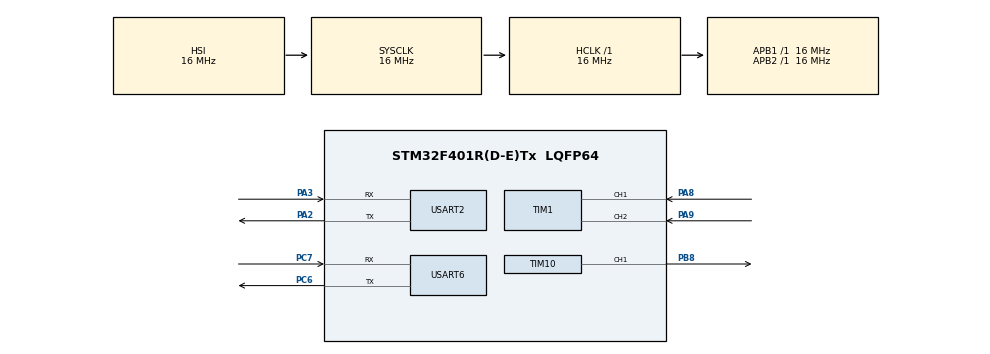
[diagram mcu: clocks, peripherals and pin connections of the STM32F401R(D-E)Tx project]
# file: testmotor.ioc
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Mcu.Family=STM32F4
Mcu.Name=STM32F401R(D-E)Tx
Mcu.Package=LQFP64
NVIC.PriorityGroup=NVIC_PRIORITYGROUP_4
PA2.Mode=Asynchronous
PA2.Signal=USART2_TX
PA3.Mode=Asynchronous
PA3.Signal=USART2_RX
PA8.Signal=S_TIM1_CH1
PA9.Signal=S_TIM1_CH2
PB8.Signal=S_TIM10_CH1
PC6.Mode=Asynchronous
PC6.Signal=USART6_TX
PC7.Mode=Asynchronous
PC7.Signal=USART6_RX
ProjectManager.HeapSize=0x200
ProjectManager.StackSize=0x400
ProjectManager.TargetToolchain=SW4STM32
RCC.AHBFreq_Value=16000000
RCC.APB1Freq_Value=16000000
RCC.APB2Freq_Value=16000000
RCC.CortexFreq_Value=16000000
RCC.HSE_VALUE=25000000
RCC.HSI_VALUE=16000000
RCC.LSE_VALUE=32768
RCC.SYSCLKFreq_VALUE=16000000
RCC.VCOOutputFreq_Value=192000000
SH.S_TIM10_CH1.0=TIM10_CH1,PWM Generation1 CH1
SH.S_TIM1_CH1.0=TIM1_CH1,Encoder_Interface
SH.S_TIM1_CH2.0=TIM1_CH2,Encoder_Interface
TIM10.Channel=TIM_CHANNEL_1
USART2.VirtualMode=VM_ASYNC
USART6.VirtualMode=VM_ASYNC
VP_TIM10_VS_ClockSourceINT.Mode=Enable_Timer
board=testmotor

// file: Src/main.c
/**
  ******************************************************************************
  * @file           : main.c
  * @brief          : Main program body
  ******************************************************************************
  ** This notice applies to any and all portions of this file
  * that are not between comment pairs USER CODE BEGIN and
  * USER CODE END. Other portions of this file, whether
  * inserted by the user or by software development tools
  * are owned by their respective copyright owners.
  *
  * COPYRIGHT(c) 2018 STMicroelectronics
  *
  * Redistribution and use in source and binary forms, with or without modification,
  * are permitted provided that the following conditions are met:
  *   1. Redistributions of source code must retain the above copyright notice,
  *      this list of conditions and the following disclaimer.
  *   2. Redistributions in binary form must reproduce the above copyright notice,
  *      this list of conditions and the following disclaimer in the documentation
  *      and/or other materials provided with the distribution.
  *   3. Neither the name of STMicroelectronics nor the names of its contributors
  *      may be used to endorse or promote products derived from this software
  *      without specific prior written permission.
  *
  * THIS SOFTWARE IS PROVIDED BY THE COPYRIGHT HOLDERS AND CONTRIBUTORS "AS IS"
  * AND ANY EXPRESS OR IMPLIED WARRANTIES, INCLUDING, BUT NOT LIMITED TO, THE
  * IMPLIED WARRANTIES OF MERCHANTABILITY AND FITNESS FOR A PARTICULAR PURPOSE ARE
  * DISCLAIMED. IN NO EVENT SHALL THE COPYRIGHT HOLDER OR CONTRIBUTORS BE LIABLE
  * FOR ANY DIRECT, INDIRECT, INCIDENTAL, SPECIAL, EXEMPLARY, OR CONSEQUENTIAL
  * DAMAGES (INCLUDING, BUT NOT LIMITED TO, PROCUREMENT OF SUBSTITUTE GOODS OR
  * SERVICES; LOSS OF USE, DATA, OR PROFITS; OR BUSINESS INTERRUPTION) HOWEVER
  * CAUSED AND ON ANY THEORY OF LIABILITY, WHETHER IN CONTRACT, STRICT LIABILITY,
  * OR TORT (INCLUDING NEGLIGENCE OR OTHERWISE) ARISING IN ANY WAY OUT OF THE USE
  * OF THIS SOFTWARE, EVEN IF ADVISED OF THE POSSIBILITY OF SUCH DAMAGE.
  *
  ******************************************************************************
  */
#include "main.h"
#include "stm32f4xx_hal.h"

TIM_HandleTypeDef htim1;
TIM_HandleTypeDef htim10;

UART_HandleTypeDef huart2;
UART_HandleTypeDef huart6;

/* USER CODE BEGIN PV */
/* Private variables ---------------------------------------------------------*/

/* USER CODE END PV */

void SystemClock_Config(void);
static void MX_GPIO_Init(void);
static void MX_TIM1_Init(void);
static void MX_USART2_UART_Init(void);
static void MX_TIM10_Init(void);
static void MX_USART6_UART_Init(void);

void HAL_TIM_MspPostInit(TIM_HandleTypeDef *htim);

/* USER CODE BEGIN PFP */
/* Private function prototypes -----------------------------------------------*/

/* USER CODE END PFP */

int main(void)
{

  /* MCU Configuration----------------------------------------------------------*/

  /* Reset of all peripherals, Initializes the Flash interface and the Systick. */
  HAL_Init();

  /* Configure the system clock */
  SystemClock_Config();

  /* Initialize all configured peripherals */
  MX_GPIO_Init();
  MX_TIM1_Init();
  MX_USART2_UART_Init();
  MX_TIM10_Init();
  MX_USART6_UART_Init();
  HAL_TIM_Encoder_Start(&htim1, TIM_CHANNEL_ALL);

  /* USER CODE BEGIN 2 */
	uint16_t cnt1 = 0, cnt2 = 0;
	uint32_t tick = 0;
	uint16_t diff = 0;
  /* USER CODE END 2 */
	uint8_t i;

	char address = 128;
	char command = 11;
	char speed = 0;
	char checksum = (address + command + speed) & 0b01111111;

	HAL_Delay(2000);
	/* HAL_UART_Transmit(&huart2, (uint8_t*)&address, sizeof(address), 0xFFFFFF);
	HAL_UART_Transmit(&huart2, (uint8_t*)&command, sizeof(command), 0xFFFFFF);

	HAL_UART_Transmit(&huart2, (uint8_t*) &speed, sizeof(speed), 0xFFFFFF);
	HAL_UART_Transmit(&huart2, (uint8_t*) &checksum, sizeof(checksum),0xFFFFFF);
	HAL_Delay(2); */

    HAL_UART_Transmit(&huart6, (uint8_t*)&address, sizeof(address), 0xFFFFFF);
    HAL_UART_Transmit(&huart6, (uint8_t*)&command, sizeof(command), 0xFFFFFF);
    HAL_UART_Transmit(&huart6, (uint8_t*)&speed, sizeof(speed), 0xFFFFFF);
    HAL_UART_Transmit(&huart6, (uint8_t*)&checksum, sizeof(checksum), 0xFFFFFF);

	HAL_Delay(2000);

	char command2 = 8;
	char speed2 = 20;

	char checksum2 = (address + command2 + speed2) & 0b01111111;
	HAL_UART_Transmit(&huart6, (uint8_t*)&address, sizeof(address), 0xFFFFFF);
	HAL_UART_Transmit(&huart6, (uint8_t*)&command2, sizeof(command2), 0xFFFFFF);
	HAL_UART_Transmit(&huart6, (uint8_t*)&speed2, sizeof(speed2), 0xFFFFFF);
	HAL_UART_Transmit(&huart6, (uint8_t*)&checksum2, sizeof(checksum2), 0xFFFFFF);

	HAL_Delay(2000);

  /* Infinite loop */
  /* USER CODE BEGIN WHILE */
    char msg[80];

	while (1) {

		if (HAL_GetTick() - tick > 1000L) {
					cnt2 = __HAL_TIM_GET_COUNTER(&htim1);
					if (__HAL_TIM_IS_TIM_COUNTING_DOWN(&htim1)) {
						if (cnt2 < cnt1)
							diff = cnt1 - cnt2;
						else
							diff = (65535 - cnt2) + cnt1;
					} else {
						if (cnt2 > cnt1)
							diff = cnt2 - cnt1;
						else
							diff = (65535 - cnt1) + cnt2;
					}

					sprintf(msg, "Difference: %d\r\n", diff);
					HAL_UART_Transmit(&huart2, (uint8_t*)msg, strlen(msg),0xFFFF);

					sprintf(msg, "CNT1: %d\r\n", cnt1);
					HAL_UART_Transmit(&huart2, (uint8_t*) msg, strlen(msg), 0xFFFF);
					sprintf(msg, "CNT2: %d\r\n", cnt2);
					HAL_UART_Transmit(&huart2, (uint8_t*) msg, strlen(msg), 0xFFFF);

					speed = ((diff / 4) / 60);

					if ((TIM1->SMCR & 0x3) == 0x3) {
						speed /= 2;
					}

					sprintf(msg, "Speed: %d\r\n", speed);
					HAL_UART_Transmit(&huart2, (uint8_t*)msg, strlen(msg),0xFFFF);

					tick = HAL_GetTick();
				    cnt1 = __HAL_TIM_GET_COUNTER(&htim1);

				}

	}
  /* USER CODE END 3 */

}

void SystemClock_Config(void)
{

  RCC_OscInitTypeDef RCC_OscInitStruct;
  RCC_ClkInitTypeDef RCC_ClkInitStruct;

    /**Configure the main internal regulator output voltage
    */
  __HAL_RCC_PWR_CLK_ENABLE();

  __HAL_PWR_VOLTAGESCALING_CONFIG(PWR_REGULATOR_VOLTAGE_SCALE2);

    /**Initializes the CPU, AHB and APB busses clocks
    */
  RCC_OscInitStruct.OscillatorType = RCC_OSCILLATORTYPE_HSI;
  RCC_OscInitStruct.HSIState = RCC_HSI_ON;
  RCC_OscInitStruct.HSICalibrationValue = 16;
  RCC_OscInitStruct.PLL.PLLState = RCC_PLL_NONE;
  if (HAL_RCC_OscConfig(&RCC_OscInitStruct) != HAL_OK)
  {
    _Error_Handler(__FILE__, __LINE__);
  }

    /**Initializes the CPU, AHB and APB busses clocks
    */
  RCC_ClkInitStruct.ClockType = RCC_CLOCKTYPE_HCLK|RCC_CLOCKTYPE_SYSCLK
                              |RCC_CLOCKTYPE_PCLK1|RCC_CLOCKTYPE_PCLK2;
  RCC_ClkInitStruct.SYSCLKSource = RCC_SYSCLKSOURCE_HSI;
  RCC_ClkInitStruct.AHBCLKDivider = RCC_SYSCLK_DIV1;
  RCC_ClkInitStruct.APB1CLKDivider = RCC_HCLK_DIV1;
  RCC_ClkInitStruct.APB2CLKDivider = RCC_HCLK_DIV1;

  if (HAL_RCC_ClockConfig(&RCC_ClkInitStruct, FLASH_LATENCY_0) != HAL_OK)
  {
    _Error_Handler(__FILE__, __LINE__);
  }

    /**Configure the Systick interrupt time
    */
  HAL_SYSTICK_Config(HAL_RCC_GetHCLKFreq()/1000);

    /**Configure the Systick
    */
  HAL_SYSTICK_CLKSourceConfig(SYSTICK_CLKSOURCE_HCLK);

  /* SysTick_IRQn interrupt configuration */
  HAL_NVIC_SetPriority(SysTick_IRQn, 0, 0);
}

/* TIM1 init function */
static void MX_TIM1_Init(void)
{

  TIM_Encoder_InitTypeDef sConfig;
  TIM_MasterConfigTypeDef sMasterConfig;

  htim1.Instance = TIM1;
  htim1.Init.Prescaler = 0;
  htim1.Init.CounterMode = TIM_COUNTERMODE_UP;
  htim1.Init.Period = 65535;
  htim1.Init.ClockDivision = TIM_CLOCKDIVISION_DIV1;
  htim1.Init.RepetitionCounter = 0;
  sConfig.EncoderMode = TIM_ENCODERMODE_TI12;
  sConfig.IC1Polarity = TIM_ICPOLARITY_RISING;
  sConfig.IC1Selection = TIM_ICSELECTION_DIRECTTI;
  sConfig.IC1Prescaler = TIM_ICPSC_DIV1;
  sConfig.IC1Filter = 0;
  sConfig.IC2Polarity = TIM_ICPOLARITY_RISING;
  sConfig.IC2Selection = TIM_ICSELECTION_DIRECTTI;
  sConfig.IC2Prescaler = TIM_ICPSC_DIV1;
  sConfig.IC2Filter = 0;
  if (HAL_TIM_Encoder_Init(&htim1, &sConfig) != HAL_OK)
  {
    _Error_Handler(__FILE__, __LINE__);
  }

  sMasterConfig.MasterOutputTrigger = TIM_TRGO_RESET;
  sMasterConfig.MasterSlaveMode = TIM_MASTERSLAVEMODE_DISABLE;
  if (HAL_TIMEx_MasterConfigSynchronization(&htim1, &sMasterConfig) != HAL_OK)
  {
    _Error_Handler(__FILE__, __LINE__);
  }

}

/* TIM10 init function */
static void MX_TIM10_Init(void)
{

  TIM_OC_InitTypeDef sConfigOC;

  htim10.Instance = TIM10;
  htim10.Init.Prescaler = 0;
  htim10.Init.CounterMode = TIM_COUNTERMODE_UP;
  htim10.Init.Period = 0;
  htim10.Init.ClockDivision = TIM_CLOCKDIVISION_DIV1;
  if (HAL_TIM_Base_Init(&htim10) != HAL_OK)
  {
    _Error_Handler(__FILE__, __LINE__);
  }

  if (HAL_TIM_PWM_Init(&htim10) != HAL_OK)
  {
    _Error_Handler(__FILE__, __LINE__);
  }

  sConfigOC.OCMode = TIM_OCMODE_PWM1;
  sConfigOC.Pulse = 0;
  sConfigOC.OCPolarity = TIM_OCPOLARITY_HIGH;
  sConfigOC.OCFastMode = TIM_OCFAST_DISABLE;
  if (HAL_TIM_PWM_ConfigChannel(&htim10, &sConfigOC, TIM_CHANNEL_1) != HAL_OK)
  {
    _Error_Handler(__FILE__, __LINE__);
  }

  HAL_TIM_MspPostInit(&htim10);

}

/* USART2 init function */
static void MX_USART2_UART_Init(void)
{

  huart2.Instance = USART2;
  huart2.Init.BaudRate = 115200;
  huart2.Init.WordLength = UART_WORDLENGTH_8B;
  huart2.Init.StopBits = UART_STOPBITS_1;
  huart2.Init.Parity = UART_PARITY_NONE;
  huart2.Init.Mode = UART_MODE_TX_RX;
  huart2.Init.HwFlowCtl = UART_HWCONTROL_NONE;
  huart2.Init.OverSampling = UART_OVERSAMPLING_16;
  if (HAL_UART_Init(&huart2) != HAL_OK)
  {
    _Error_Handler(__FILE__, __LINE__);
  }

}

/* USART6 init function */
static void MX_USART6_UART_Init(void)
{

  huart6.Instance = USART6;
  huart6.Init.BaudRate = 38400;
  huart6.Init.WordLength = UART_WORDLENGTH_8B;
  huart6.Init.StopBits = UART_STOPBITS_1;
  huart6.Init.Parity = UART_PARITY_NONE;
  huart6.Init.Mode = UART_MODE_TX_RX;
  huart6.Init.HwFlowCtl = UART_HWCONTROL_NONE;
  huart6.Init.OverSampling = UART_OVERSAMPLING_16;
  if (HAL_UART_Init(&huart6) != HAL_OK)
  {
    _Error_Handler(__FILE__, __LINE__);
  }

}

/** Pinout Configuration
*/
static void MX_GPIO_Init(void)
{

  /* GPIO Ports Clock Enable */
  __HAL_RCC_GPIOA_CLK_ENABLE();
  __HAL_RCC_GPIOC_CLK_ENABLE();
  __HAL_RCC_GPIOB_CLK_ENABLE();

}

void _Error_Handler(char *file, int line)
{
  while(1)
  {
  }
}

/************************ (C) COPYRIGHT STMicroelectronics *****END OF FILE****/
